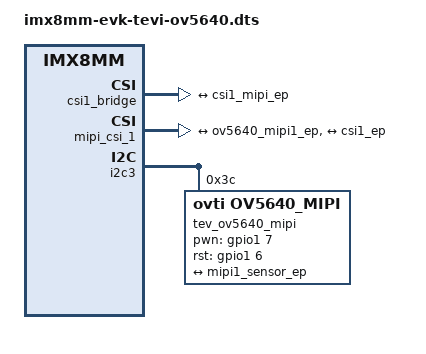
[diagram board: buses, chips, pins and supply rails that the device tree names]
// SPDX-License-Identifier: (GPL-2.0+ OR MIT)
/*
 * Copyright 2021 Technexion Ltd.
 *
 * This program is free software; you can redistribute it and/or
 * modify it under the terms of the GNU General Public License
 * as published by the Free Software Foundation; either version 2
 * of the License, or (at your option) any later version.
 *
 * This program is distributed in the hope that it will be useful,
 * but WITHOUT ANY WARRANTY; without even the implied warranty of
 * MERCHANTABILITY or FITNESS FOR A PARTICULAR PURPOSE.  See the
 * GNU General Public License for more details.
 */

#include "imx8mm-evk.dts"

&pcie0{
	status = "disabled";
};

&csi1_bridge {
	fsl,mipi-mode;
	status = "okay";
	port {
		csi1_ep: endpoint {
			remote-endpoint = <&csi1_mipi_ep>;
		};
	};
};

&mipi_csi_1 {
	#address-cells = <1>;
	#size-cells = <0>;
	status = "okay";
	port {
		mipi1_sensor_ep: endpoint@1 {
			remote-endpoint = <&ov5640_mipi1_ep>;
			data-lanes = <2>;
			csis-hs-settle = <13>;
			csis-clk-settle = <2>;
			csis-wclk;
		};

		csi1_mipi_ep: endpoint@2 {
			remote-endpoint = <&csi1_ep>;
		};
	};
};

&i2c3 {
	/delete-node/ ov5640_mipi@3c;

	tev_ov5640_mipi@3c {
		compatible = "ovti,ov5640_mipi";
		reg = <0x3c>;
		status = "okay";
		pinctrl-names = "default";
		pinctrl-0 = <&pinctrl_csi_pwn>, <&pinctrl_csi_rst>;
		clocks = <&clk IMX8MM_CLK_CLKO1>;
		clock-names = "csi_mclk";
		assigned-clocks = <&clk IMX8MM_CLK_CLKO1>;
		assigned-clock-parents = <&clk IMX8MM_CLK_24M>;
		assigned-clock-rates = <24000000>;
		csi_id = <0>;
		pwn-gpios = <&gpio1 7 GPIO_ACTIVE_HIGH>;
		rst-gpios = <&gpio1 6 GPIO_ACTIVE_HIGH>;
		mclk = <24000000>;
		mclk_source = <0>;
		port {
			ov5640_mipi1_ep: endpoint {
				remote-endpoint = <&mipi1_sensor_ep>;
			};
		};
	};
};
